# HDSC_HC32F472 register map
Vendor: HDSC; Series: ARMCM4; File version: 1.0
CPU: CM4 r0p1, little endian, MPU, FPU, 4 interrupt priority bits
Registers are 32-bit, read-write, reset 0x0 unless marked. A register's access mark holds for its fields unless they carry their own. Offsets are from the block's base; [hi:lo] are bit positions; {n}, {i} and the like mark numbered series; 'fields as' and 'values as' point back to an identical list.

## RTC
Base 0x4004C000
0x00 CR0 8-bit
  [0] RESET
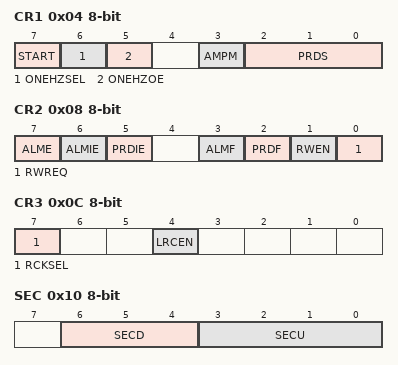
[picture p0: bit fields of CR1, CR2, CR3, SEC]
0x04 CR1 8-bit
  [7] START, [6] ONEHZSEL, [5] ONEHZOE, [3] AMPM, [2:0] PRDS
0x08 CR2 8-bit
  [7] ALME, [6] ALMIE, [5] PRDIE, [3] ALMF, [2] PRDF, [1] RWEN, [0] RWREQ
0x0C CR3 8-bit
  [7] RCKSEL, [4] LRCEN
0x10 SEC 8-bit
  [6:4] SECD, [3:0] SECU
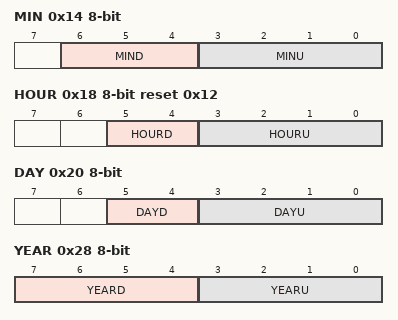
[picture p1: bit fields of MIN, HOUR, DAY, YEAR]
0x14 MIN 8-bit
  [6:4] MIND, [3:0] MINU
0x18 HOUR 8-bit reset 0x12
  [5:4] HOURD, [3:0] HOURU
0x1C WEEK 8-bit
  [2:0] WEEK
0x20 DAY 8-bit
  [5:4] DAYD, [3:0] DAYU
0x24 MON 8-bit
  [4:0] MON
0x28 YEAR 8-bit
  [7:4] YEARD, [3:0] YEARU
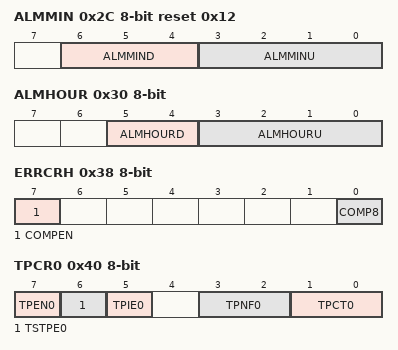
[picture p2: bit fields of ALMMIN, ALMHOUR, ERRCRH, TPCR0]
0x2C ALMMIN 8-bit reset 0x12
  [6:4] ALMMIND, [3:0] ALMMINU
0x30 ALMHOUR 8-bit
  [5:4] ALMHOURD, [3:0] ALMHOURU
0x34 ALMWEEK 8-bit
  [6:0] ALMWEEK
0x38 ERRCRH 8-bit
  [7] COMPEN, [0] COMP8
0x3C ERRCRL 8-bit
  [7:0] COMP
0x40 TPCR0 8-bit
  [7] TPEN0, [6] TSTPE0, [5] TPIE0, [3:2] TPNF0, [1:0] TPCT0
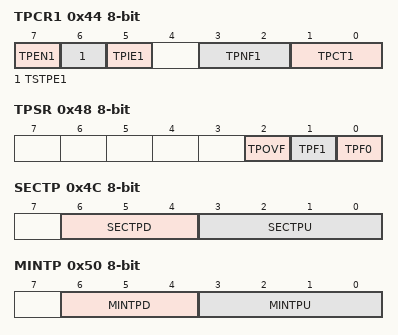
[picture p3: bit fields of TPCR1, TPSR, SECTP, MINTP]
0x44 TPCR1 8-bit
  [7] TPEN1, [6] TSTPE1, [5] TPIE1, [3:2] TPNF1, [1:0] TPCT1
0x48 TPSR 8-bit
  [2] TPOVF, [1] TPF1, [0] TPF0
0x4C SECTP 8-bit
  [6:4] SECTPD, [3:0] SECTPU
0x50 MINTP 8-bit
  [6:4] MINTPD, [3:0] MINTPU
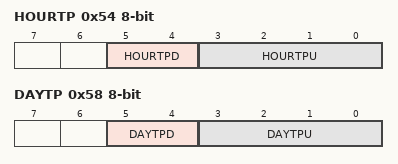
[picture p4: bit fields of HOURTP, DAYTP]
0x54 HOURTP 8-bit
  [5:4] HOURTPD, [3:0] HOURTPU
0x58 DAYTP 8-bit
  [5:4] DAYTPD, [3:0] DAYTPU
0x5C MONTP 8-bit
  [4:0] MONTP

## SMC
Base 0x88000000
0x00 STSR ro reset 0x1
  [0] STATUS
0x08 STCR0 wo
  [2] LPWIR
0x0C STCR1 wo
  [2] LPWOR
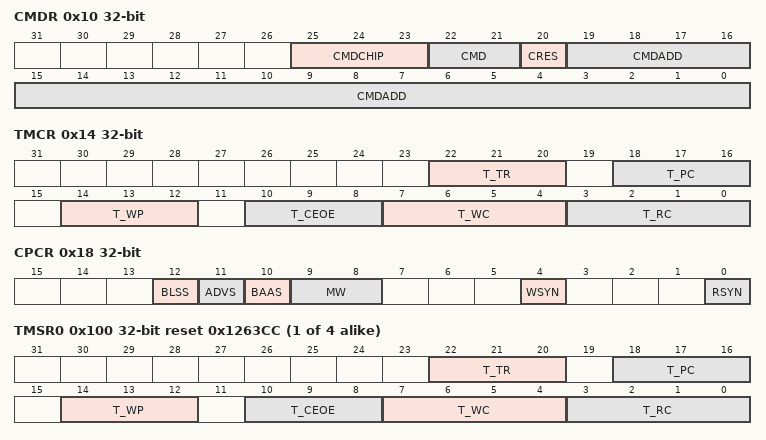
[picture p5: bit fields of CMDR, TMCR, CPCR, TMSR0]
0x10 CMDR wo
  [25:23] CMDCHIP, [22:21] CMD, [20] CRES, [19:0] CMDADD
0x14 TMCR wo
  [22:20] T_TR, [18:16] T_PC, [14:12] T_WP, [10:8] T_CEOE, [7:4] T_WC, [3:0] T_RC
0x18 CPCR wo
  [12] BLSS, [11] ADVS, [10] BAAS, [9:8] MW, [4] WSYN, [0] RSYN
0x20 RFTR
  [3:0] REFPRD
{0x100+0x20*i} TMSR{i} ro reset 0x1263CC (i=0..3)
  fields as TMCR
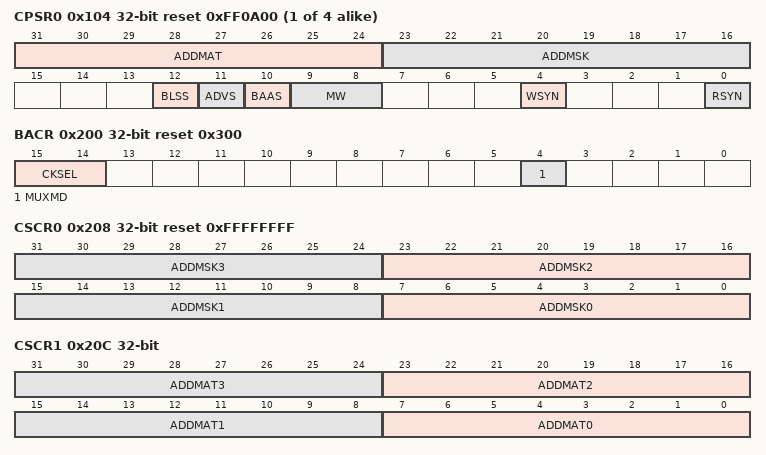
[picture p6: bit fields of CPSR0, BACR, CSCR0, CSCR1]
{0x104+0x20*i} CPSR{i} ro reset 0xFF0A00 (i=0..3)
  [31:24] ADDMAT, [23:16] ADDMSK, [12] BLSS, [11] ADVS, [10] BAAS, [9:8] MW, [4] WSYN, [0] RSYN
0x200 BACR reset 0x300
  [15:14] CKSEL, [4] MUXMD
0x208 CSCR0 reset 0xFFFFFFFF
  [8n+7:8n] ADDMSK{n} (n=0..3)
0x20C CSCR1
  [8n+7:8n] ADDMAT{n} (n=0..3)

## SPI1 — desc SPI
Base 0x4001C000
Same registers: SPI2 0x4001C400, SPI3 0x4001C800, SPI4 0x40020000
0x00 DR
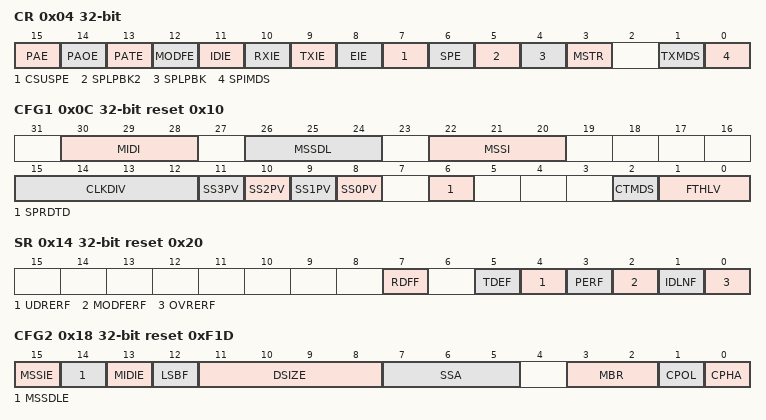
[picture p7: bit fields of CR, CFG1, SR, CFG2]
0x04 CR
  [15] PAE, [14] PAOE, [13] PATE, [12] MODFE, [11] IDIE, [10] RXIE, [9] TXIE, [8] EIE, [7] CSUSPE, [6] SPE, [5] SPLPBK2, [4] SPLPBK, [3] MSTR, [1] TXMDS, [0] SPIMDS
0x0C CFG1 reset 0x10
  [30:28] MIDI, [26:24] MSSDL, [22:20] MSSI, [15:12] CLKDIV, [n+8] SS{n}PV (n=0..3), [6] SPRDTD, [2] CTMDS, [1:0] FTHLV
0x14 SR reset 0x20
  [7] RDFF ro, [5] TDEF ro, [4] UDRERF, [3] PERF, [2] MODFERF, [1] IDLNF ro, [0] OVRERF
0x18 CFG2 reset 0xF1D
  [15] MSSIE, [14] MSSDLE, [13] MIDIE, [12] LSBF, [11:8] DSIZE, [7:5] SSA, [3:2] MBR, [1] CPOL, [0] CPHA

## SRAMC
Base 0x40050800
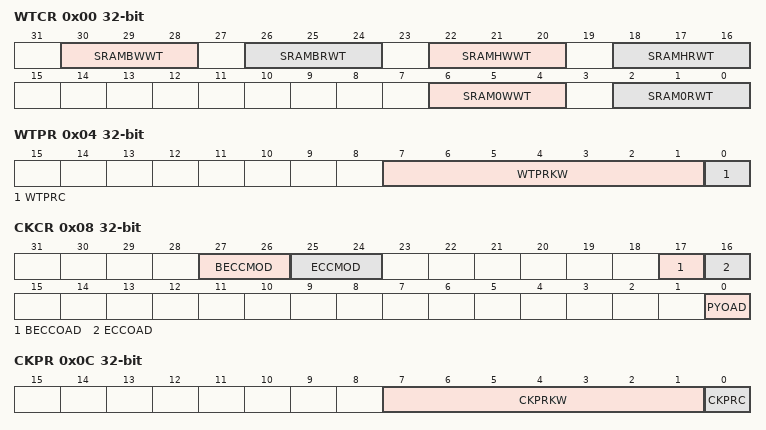
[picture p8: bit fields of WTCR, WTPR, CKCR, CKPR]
0x00 WTCR
  [30:28] SRAMBWWT, [26:24] SRAMBRWT, [22:20] SRAMHWWT, [18:16] SRAMHRWT, [6:4] SRAM0WWT, [2:0] SRAM0RWT
0x04 WTPR
  [7:1] WTPRKW, [0] WTPRC
0x08 CKCR
  [27:26] BECCMOD, [25:24] ECCMOD, [17] BECCOAD, [16] ECCOAD, [0] PYOAD
0x0C CKPR
  [7:1] CKPRKW, [0] CKPRC
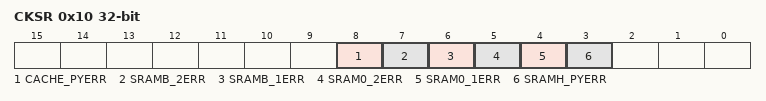
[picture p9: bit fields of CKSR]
0x10 CKSR
  [8] CACHE_PYERR, [7] SRAMB_2ERR, [6] SRAMB_1ERR, [5] SRAM0_2ERR, [4] SRAM0_1ERR, [3] SRAMH_PYERR
0x14 SRAM0_EIEN
  [0] EIEN
0x18 SRAM0_EIBIT0
0x1C SRAM0_EIBIT1
  [6:0] EIBIT
0x20 SRAM0_ECCERRADDR
  [14:0] ECCERRADDR
0x24 SRAMB_EIEN
  [0] EIEN
0x28 SRAMB_EIBIT0
0x2C SRAMB_EIBIT1
  [6:0] EIBIT
0x30 SRAMB_ECCERRADDR
  [11:0] ECCERRADDR

## SWDT
Base 0x40049400
Same registers: WDT 0x40049000
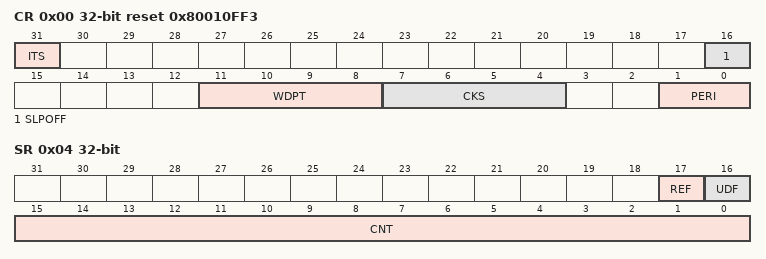
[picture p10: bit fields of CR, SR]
0x00 CR reset 0x80010FF3
  [31] ITS, [16] SLPOFF, [11:8] WDPT, [7:4] CKS, [1:0] PERI
0x04 SR
  [17] REF, [16] UDF, [15:0] CNT ro
0x08 RR
  [15:0] RF

## TMR01 — desc TMR0
Base 0x40024000
Same registers: TMR02 0x40024400
0x00 CNTAR
  [15:0] CNTA
0x04 CNTBR
  [15:0] CNTB
0x08 CMPAR reset 0xFFFF
  [15:0] CMPA
0x0C CMPBR reset 0xFFFF
  [15:0] CMPB
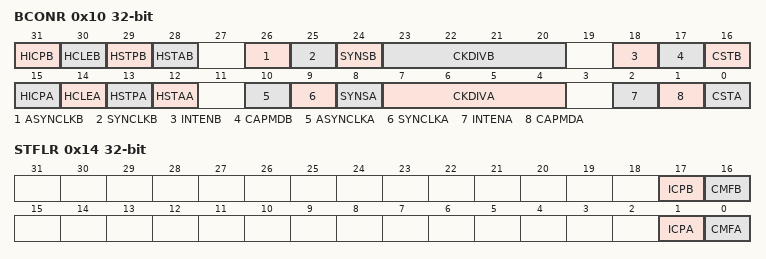
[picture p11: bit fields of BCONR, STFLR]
0x10 BCONR
  [31] HICPB, [30] HCLEB, [29] HSTPB, [28] HSTAB, [26] ASYNCLKB, [25] SYNCLKB, [24] SYNSB, [23:20] CKDIVB, [18] INTENB, [17] CAPMDB, [16] CSTB, [15] HICPA, [14] HCLEA, [13] HSTPA, [12] HSTAA, [10] ASYNCLKA, [9] SYNCLKA, [8] SYNSA, [7:4] CKDIVA, [2] INTENA, [1] CAPMDA, [0] CSTA
0x14 STFLR
  [17] ICPB, [16] CMFB, [1] ICPA, [0] CMFA
